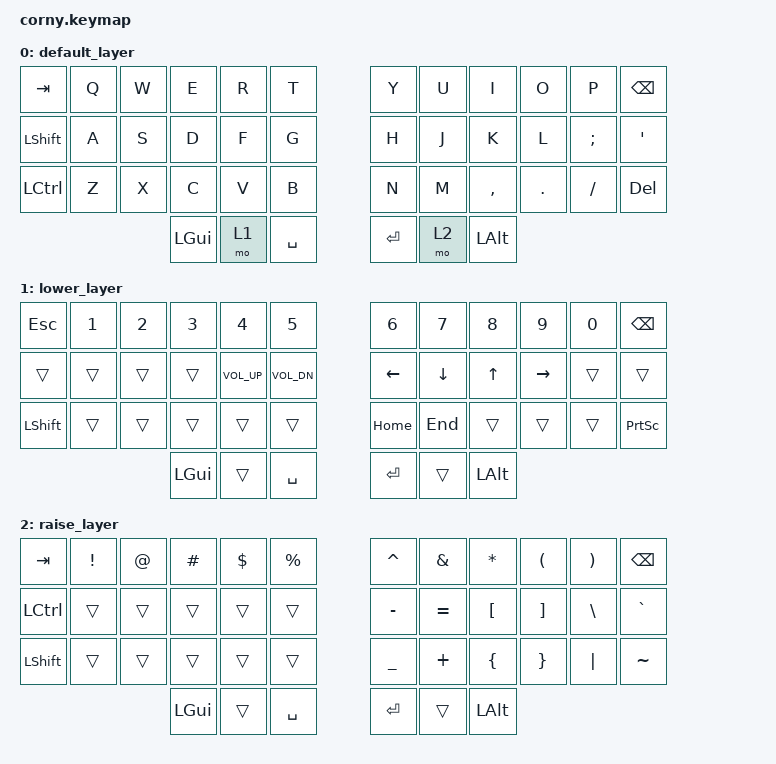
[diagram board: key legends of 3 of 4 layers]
/*
 * Copyright (c) 2020 The ZMK Contributors
 *
 * SPDX-License-Identifier: MIT
 */

#include <behaviors.dtsi>
#include <dt-bindings/zmk/keys.h>
#include <dt-bindings/zmk/bt.h>

/ {
        conditional_layers {
                compatible = "zmk,conditional-layers";
        
                adjust_layer {
                    if-layers = <1 2>;
                    then-layer = <3>;
                };
        };

        keymap {
                compatible = "zmk,keymap";

                default_layer {
// -----------------------------------------------------------------------------------------
// |  TAB |  Q  |  W  |  E  |  R  |  T  |   |  Y  |  U   |  I  |  O  |  P  | BKSP |
// | SHFT |  A  |  S  |  D  |  F  |  G  |   |  H  |  J   |  K  |  L  |  ;  |  '   |
// | CTRL |  Z  |  X  |  C  |  V  |  B  |   |  N  |  M   |  ,  |  .  |  /  | DEL  |
//                    | GUI | LWR | SPC |   | ENT | RSE  | ALT |
                        bindings = <
   &kp TAB   &kp Q &kp W &kp E &kp R &kp T   &kp Y &kp U  &kp I     &kp O   &kp P    &kp BSPC
   &kp LSHFT &kp A &kp S &kp D &kp F &kp G   &kp H &kp J  &kp K     &kp L   &kp SEMI &kp SQT
   &kp LCTRL &kp Z &kp X &kp C &kp V &kp B   &kp N &kp M  &kp COMMA &kp DOT &kp FSLH &kp DEL
                  &kp LGUI &mo 1 &kp SPACE   &kp RET &mo 2 &kp LALT
                        >;
                };
                lower_layer {
// -----------------------------------------------------------------------------------------
// |  ESC |  1  |  2  |  3  |  4  |  5  |   |  6  |  7  |  8  |  9  |  0  | BKSP |
// |      |     |     |     |VOLUP|VOLDN|   | LFT | DWN |  UP | RGT |     |      |
// | SHFT |     |     |     |     |     |   | HOME|END  |     |     |     | PSCR |
//                    | GUI |     | SPC |   | ENT |     | ALT |
                        bindings = <
   &kp ESC    &kp N1       &kp N2       &kp N3       &kp N4       &kp N5         &kp N6   &kp N7   &kp N8 &kp N9    &kp N0 &kp BSPC
   &trans     &trans       &trans       &trans       &kp C_VOL_UP &kp C_VOL_DN   &kp LEFT &kp DOWN &kp UP &kp RIGHT &trans &trans 
   &kp LSHFT  &trans       &trans       &trans       &trans       &trans         &kp HOME   &kp END   &trans &trans    &trans &kp PRINTSCREEN
                                    &kp LGUI     &trans       &kp SPACE      &kp RET  &trans   &kp LALT
                        >;
                };

                raise_layer {
// -----------------------------------------------------------------------------------------
// |  TAB |  !  |  @  |  #  |  $  |  %  |   |  ^  |  &  |  *  |  (  |  )  | BKSP |
// | CTRL |     |     |     |     |     |   |  -  |  =  |  [  |  ]  |  \  |  `   |
// | SHFT |     |     |     |     |     |   |  _  |  +  |  {  |  }  | "|" |  ~   |
//                    | GUI |     | SPC |   | ENT |     | ALT |
                        bindings = <
   &kp  TAB  &kp EXCL &kp AT &kp HASH &kp DLLR &kp PRCNT   &kp CARET &kp AMPS  &kp ASTRK &kp LPAR &kp RPAR &kp BSPC
   &kp LCTRL &trans   &trans &trans   &trans   &trans      &kp MINUS &kp EQUAL &kp LBKT  &kp RBKT &kp BSLH &kp GRAVE
   &kp LSHFT &trans   &trans &trans   &trans   &trans      &kp UNDER &kp PLUS  &kp LBRC  &kp RBRC &kp PIPE &kp TILDE
                             &kp LGUI &trans   &kp SPACE   &kp RET   &trans    &kp LALT
                        >;
                };
                
        // ------------------------------------------------------------------------------------------------------------
        // |BTCLR | BT1   | BT2   |  BT3  |  BT4  |  BT5  |                |      |      |       |      |       |       |
        // |      |       |       |       |       |       |                |      |      |       |      |       |       |
        // |      |       |       |       |       |       |                |      |      |       |      |       |       |
        // |      |       |       |       |       |       |       | |      |      |      |       |      |       |       |
        //                |       |       |       |       |       | |      |      |      |       |      |

        Adjust_layer {
            bindings = <
&bt BT_CLR                       &bt BT_SEL 0     &bt BT_SEL 1     &bt BT_SEL 2     &bt BT_SEL 3     &bt BT_SEL 4                               &none  &none  &none  &none  &none  &none
&none           &none            &none            &none            &none            &none                                                       &none  &none  &none  &none  &none  &none
&none                            &none            &none            &none            &none            &none                                      &none  &none  &none  &none  &none  &none
&none                            &none            &none            &none            &none            &none            &none              &none  &none  &none  &none  &none  &none  &none
                                                  &none            &none            &none            &none            &none              &none  &none  &none  &none  &none
            >;
                };
        };
};
